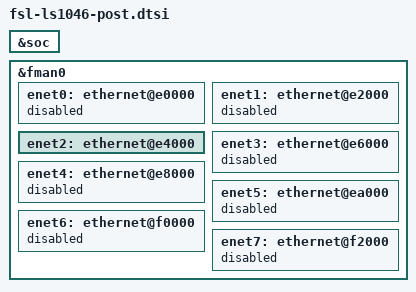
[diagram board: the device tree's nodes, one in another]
// SPDX-License-Identifier: (GPL-2.0+ OR BSD-3-Clause)
/*
 * QorIQ FMan v3 device tree nodes for ls1046
 *
 * Copyright 2015-2016 Freescale Semiconductor Inc.
 * Copyright 2020 NXP
 *
 */

&soc {

/* include used FMan blocks */
#include "qoriq-fman3-0.dtsi"
#include "qoriq-fman3-0-1g-0.dtsi"
#include "qoriq-fman3-0-1g-1.dtsi"
#include "qoriq-fman3-0-1g-2.dtsi"
#include "qoriq-fman3-0-1g-3.dtsi"
#include "qoriq-fman3-0-1g-4.dtsi"
#include "qoriq-fman3-0-1g-5.dtsi"
#include "qoriq-fman3-0-10g-0.dtsi"
#include "qoriq-fman3-0-10g-1.dtsi"
};

&fman0 {
	/* these aliases provide the FMan ports mapping */
	enet0: ethernet@e0000 {
	status = "disabled";
	};

	enet1: ethernet@e2000 {
	status = "disabled";
	};

	enet2: ethernet@e4000 {
	};

	enet3: ethernet@e6000 {
	status = "disabled";
	};

	enet4: ethernet@e8000 {
	status = "disabled";
	};

	enet5: ethernet@ea000 {
	status = "disabled";
	};

	enet6: ethernet@f0000 {
	status = "disabled";
	};

	enet7: ethernet@f2000 {
	status = "disabled";
	};
};
